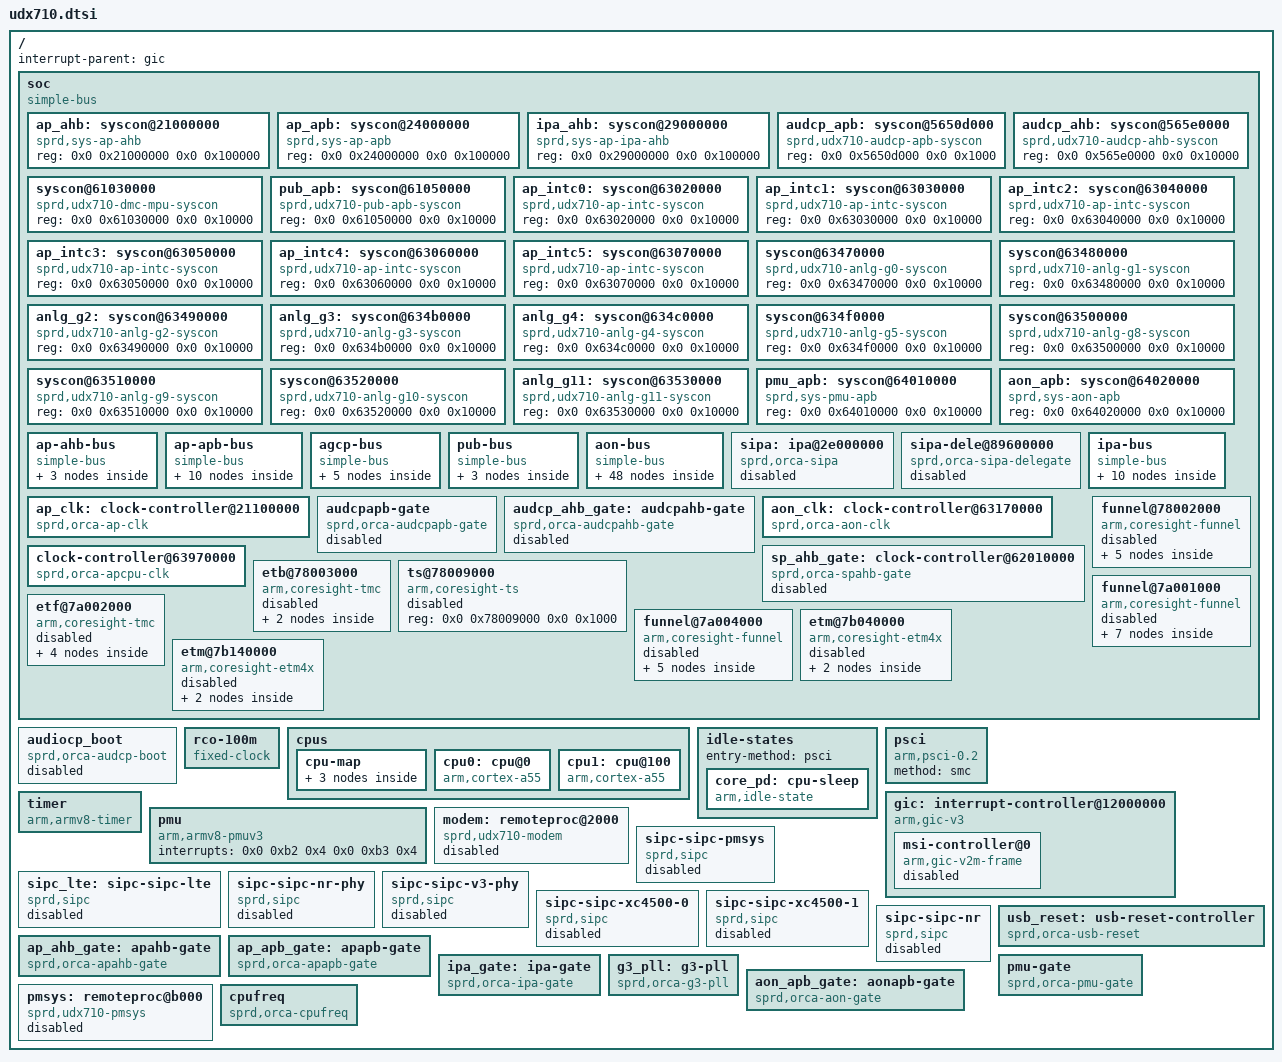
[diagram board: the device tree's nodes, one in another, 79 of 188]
// SPDX-License-Identifier: GPL-2.0-only
/* UDX710 controllers and silicon resources. The board supplies ext_26m and
 * ext_32k clock inputs and selects CPU frequency policy. */

/ {
	interrupt-parent = <&gic>;
	#address-cells = <0x2>;
	#size-cells = <0x2>;
	soc {
		compatible = "simple-bus";
		#address-cells = <0x2>;
		#size-cells = <0x2>;
		ranges;
		ap_ahb: syscon@21000000 {
			compatible = "sprd,sys-ap-ahb", "syscon";
			#syscon-cells = <0x2>;
			reg = <0x0 0x21000000 0x0 0x100000>;
		};
		ap_apb: syscon@24000000 {
			compatible = "sprd,sys-ap-apb", "syscon";
			#syscon-cells = <0x2>;
			reg = <0x0 0x24000000 0x0 0x100000>;
		};
		ipa_ahb: syscon@29000000 {
			compatible = "sprd,sys-ap-ipa-ahb", "syscon";
			#syscon-cells = <0x2>;
			reg = <0x0 0x29000000 0x0 0x100000>;
		};
		audcp_apb: syscon@5650d000 {
			compatible = "sprd,udx710-audcp-apb-syscon", "syscon";
			#syscon-cells = <0x2>;
			reg = <0x0 0x5650d000 0x0 0x1000>;
		};
		audcp_ahb: syscon@565e0000 {
			compatible = "sprd,udx710-audcp-ahb-syscon", "syscon";
			#syscon-cells = <0x2>;
			reg = <0x0 0x565e0000 0x0 0x10000>;
		};
		syscon@61030000 {
			compatible = "sprd,udx710-dmc-mpu-syscon", "syscon";
			#syscon-cells = <0x2>;
			reg = <0x0 0x61030000 0x0 0x10000>;
		};
		pub_apb: syscon@61050000 {
			compatible = "sprd,udx710-pub-apb-syscon", "syscon";
			#syscon-cells = <0x2>;
			reg = <0x0 0x61050000 0x0 0x10000>;
		};
		ap_intc0: syscon@63020000 {
			compatible = "sprd,udx710-ap-intc-syscon", "syscon";
			#syscon-cells = <0x2>;
			reg = <0x0 0x63020000 0x0 0x10000>;
		};
		ap_intc1: syscon@63030000 {
			compatible = "sprd,udx710-ap-intc-syscon", "syscon";
			#syscon-cells = <0x2>;
			reg = <0x0 0x63030000 0x0 0x10000>;
		};
		ap_intc2: syscon@63040000 {
			compatible = "sprd,udx710-ap-intc-syscon", "syscon";
			#syscon-cells = <0x2>;
			reg = <0x0 0x63040000 0x0 0x10000>;
		};
		ap_intc3: syscon@63050000 {
			compatible = "sprd,udx710-ap-intc-syscon", "syscon";
			#syscon-cells = <0x2>;
			reg = <0x0 0x63050000 0x0 0x10000>;
		};
		ap_intc4: syscon@63060000 {
			compatible = "sprd,udx710-ap-intc-syscon", "syscon";
			#syscon-cells = <0x2>;
			reg = <0x0 0x63060000 0x0 0x10000>;
		};
		ap_intc5: syscon@63070000 {
			compatible = "sprd,udx710-ap-intc-syscon", "syscon";
			#syscon-cells = <0x2>;
			reg = <0x0 0x63070000 0x0 0x10000>;
		};
		syscon@63470000 {
			compatible = "sprd,udx710-anlg-g0-syscon", "syscon";
			#syscon-cells = <0x2>;
			reg = <0x0 0x63470000 0x0 0x10000>;
		};
		syscon@63480000 {
			compatible = "sprd,udx710-anlg-g1-syscon", "syscon";
			#syscon-cells = <0x2>;
			reg = <0x0 0x63480000 0x0 0x10000>;
		};
		anlg_g2: syscon@63490000 {
			compatible = "sprd,udx710-anlg-g2-syscon", "syscon";
			#syscon-cells = <0x2>;
			reg = <0x0 0x63490000 0x0 0x10000>;
		};
		anlg_g3: syscon@634b0000 {
			compatible = "sprd,udx710-anlg-g3-syscon", "syscon";
			#syscon-cells = <0x2>;
			reg = <0x0 0x634b0000 0x0 0x10000>;
		};
		anlg_g4: syscon@634c0000 {
			compatible = "sprd,udx710-anlg-g4-syscon", "syscon";
			#syscon-cells = <0x2>;
			reg = <0x0 0x634c0000 0x0 0x10000>;
		};
		syscon@634f0000 {
			compatible = "sprd,udx710-anlg-g5-syscon", "syscon";
			#syscon-cells = <0x2>;
			reg = <0x0 0x634f0000 0x0 0x10000>;
		};
		syscon@63500000 {
			compatible = "sprd,udx710-anlg-g8-syscon", "syscon";
			#syscon-cells = <0x2>;
			reg = <0x0 0x63500000 0x0 0x10000>;
		};
		syscon@63510000 {
			compatible = "sprd,udx710-anlg-g9-syscon", "syscon";
			#syscon-cells = <0x2>;
			reg = <0x0 0x63510000 0x0 0x10000>;
		};
		syscon@63520000 {
			compatible = "sprd,udx710-anlg-g10-syscon", "syscon";
			#syscon-cells = <0x2>;
			reg = <0x0 0x63520000 0x0 0x10000>;
		};
		anlg_g11: syscon@63530000 {
			compatible = "sprd,udx710-anlg-g11-syscon", "syscon";
			#syscon-cells = <0x2>;
			reg = <0x0 0x63530000 0x0 0x10000>;
		};
		pmu_apb: syscon@64010000 {
			compatible = "sprd,sys-pmu-apb", "syscon";
			#syscon-cells = <0x2>;
			reg = <0x0 0x64010000 0x0 0x10000>;
		};
		aon_apb: syscon@64020000 {
			compatible = "sprd,sys-aon-apb", "syscon";
			#syscon-cells = <0x2>;
			reg = <0x0 0x64020000 0x0 0x10000>;
		};
		ap-ahb-bus {
			compatible = "simple-bus";
			#address-cells = <0x2>;
			#size-cells = <0x2>;
			ranges;
			ap_dma: dma-controller@21200000 {
				compatible = "sprd,orca-dma";
				reg = <0x0 0x21200000 0x0 0x4000>;
				interrupts = <0x0 0x32 0x4>;
				#dma-cells = <0x1>;
				clock-names = "enable";
				clocks = <&ap_ahb_gate 0x4>;
				dma-channels = <0x1c>;
			};
			nand-controller@21300000 {
			status = "disabled";
				compatible = "sprd,orca-nandc";
				reg = <0x0 0x21300000 0x0 0x1000>;
				interrupts = <0x0 0x3b 0x4>;
				clock-names = "nandc_clk", "nandc_ecc_clk", "nandc_parent_sdr", "nandc_parent_ddr", "nandc_ahb_enable", "nandc_ecc_enable", "nandc_26m_enable", "nandc_1x_enable", "nandc_2x_enable";
				clocks = <&aon_clk 0x2e &ap_clk 0x2 &g3_pll 0xf &g3_pll 0xe &ap_ahb_gate 0x1 &ap_ahb_gate 0x2 &ap_ahb_gate 0x3 &aon_apb_gate 0x69 &aon_apb_gate 0x6a>;
				#address-cells = <0x1>;
				#size-cells = <0x0>;
			};
			sdio@26100000 {
				status = "disabled";
				compatible = "sprd,sdhc-r11p1";
				reg = <0x0 0x26100000 0x0 0x1000>;
				interrupts = <0x0 0x3c 0x4>;
				clock-names = "sdio_clk", "sdio_clk_source", "sdio_ahb_enable";
				clocks = <&aon_clk 0x2c &g3_pll 0x0 &ap_ahb_gate 0xb>;
			};
		};
		ap-apb-bus {
			compatible = "simple-bus";
			#address-cells = <0x2>;
			#size-cells = <0x2>;
			ranges;
			serial@24100000 {
			status = "disabled";
				compatible = "sprd,sc9836-uart";
				reg = <0x0 0x24100000 0x0 0x100>;
				interrupts = <0x0 0x3 0x4>;
				clock-names = "enable", "uart", "source";
				clocks = <&ap_apb_gate 0x1 &ap_clk 0x6 &ext_26m>;
			};
			i2c@24200000 {
				compatible = "sprd,orca-i2c";
				reg = <0x0 0x24200000 0x0 0x1000>;
				interrupts = <0x0 0xb 0x4>;
				clock-frequency = <0x61a80>;
				#address-cells = <0x1>;
				#size-cells = <0x0>;
				status = "disabled";
				clock-names = "enable", "i2c", "source";
				clocks = <&ap_apb_gate 0x2 &ap_clk 0x7 &ext_26m>;
			};
			i2c@24300000 {
				compatible = "sprd,orca-i2c";
				reg = <0x0 0x24300000 0x0 0x1000>;
				interrupts = <0x0 0xc 0x4>;
				clock-frequency = <0x61a80>;
				#address-cells = <0x1>;
				#size-cells = <0x0>;
				status = "disabled";
				clock-names = "enable", "i2c", "source";
				clocks = <&ap_apb_gate 0x3 &ap_clk 0x8 &ext_26m>;
			};
			i2c@24400000 {
				compatible = "sprd,orca-i2c";
				reg = <0x0 0x24400000 0x0 0x1000>;
				interrupts = <0x0 0xd 0x4>;
				clock-frequency = <0x61a80>;
				#address-cells = <0x1>;
				#size-cells = <0x0>;
				status = "disabled";
				clock-names = "enable", "i2c", "source";
				clocks = <&ap_apb_gate 0x4 &ap_clk 0x9 &ext_26m>;
			};
			i2c@24500000 {
				compatible = "sprd,orca-i2c";
				reg = <0x0 0x24500000 0x0 0x1000>;
				interrupts = <0x0 0xe 0x4>;
				clock-frequency = <0x61a80>;
				#address-cells = <0x1>;
				#size-cells = <0x0>;
				status = "disabled";
				clock-names = "enable", "i2c", "source";
				clocks = <&ap_apb_gate 0x5 &ap_clk 0xa &ext_26m>;
			};
			i2c@24600000 {
				compatible = "sprd,orca-i2c";
				reg = <0x0 0x24600000 0x0 0x1000>;
				interrupts = <0x0 0xf 0x4>;
				clock-frequency = <0x61a80>;
				#address-cells = <0x1>;
				#size-cells = <0x0>;
				status = "disabled";
				clock-names = "enable", "i2c", "source";
				clocks = <&ap_apb_gate 0x6 &ap_clk 0xb &ext_26m>;
			};
			spi@24700000 {
				compatible = "sprd,sc9860-spi", "sprd,orca-spi";
				reg = <0x0 0x24700000 0x0 0x1000>;
				interrupts = <0x0 0x7 0x4>;
				#address-cells = <0x1>;
				#size-cells = <0x0>;
				status = "disabled";
				clock-names = "enable", "spi", "source";
				clocks = <&ap_apb_gate 0x7 &aon_clk 0x30 &g3_pll 0x5>;
			};
			spi@24800000 {
				compatible = "sprd,sc9860-spi", "sprd,orca-spi";
				reg = <0x0 0x24800000 0x0 0x1000>;
				interrupts = <0x0 0x8 0x4>;
				#address-cells = <0x1>;
				#size-cells = <0x0>;
				status = "disabled";
				clock-names = "enable", "spi", "source";
				clocks = <&ap_apb_gate 0x9 &aon_clk 0x31 &g3_pll 0x5>;
			};
			spi@24900000 {
				compatible = "sprd,sc9860-spi", "sprd,orca-spi";
				reg = <0x0 0x24900000 0x0 0x1000>;
				interrupts = <0x0 0x9 0x4>;
				#address-cells = <0x1>;
				#size-cells = <0x0>;
				status = "disabled";
				clock-names = "enable", "spi", "source";
				clocks = <&ap_apb_gate 0xb &aon_clk 0x32 &g3_pll 0x5>;
			};
			i2s0: i2s@25000000 {
				compatible = "sprd,i2s";
				status = "disabled";
			};
		};
		agcp-bus {
			compatible = "simple-bus";
			#address-cells = <0x2>;
			#size-cells = <0x2>;
			ranges;
			vbc: vbc@56480000 {
				compatible = "sprd,roc1-vbc";
				#sound-dai-cells = <0x1>;
				reg = <0x0 0x56480000 0x0 0x1000>;
				sprd,syscon-agcp-ahb = <&audcp_ahb>;
				sprd,vbc-phy-offset = <0x55000000>;
				status = "disabled";
			};
			mcdt@56490000 {
				compatible = "sprd,roc1-mcdt";
				reg = <0x0 0x56490000 0x0 0x170>;
				interrupts = <0x0 0x76 0x4>;
				sprd,ap-addr-offset = <0x55000000>;
				status = "disabled";
			};
			audcp_dma: dma-controller@56580000 {
				compatible = "sprd,roc1-dma";
				reg = <0x0 0x56580000 0x0 0x4000>;
				interrupts = <0x0 0x75 0x4>;
				#dma-cells = <0x1>;
				#dma-channels = <0x20>;
				clock-names = "enable", "ashb_eb";
				clocks = <&audcp_ahb_gate 0x6 &audcp_ahb_gate 0xd>;
				status = "disabled";
			};
			audio-codec@56750000 {
				compatible = "sprd,audio-codec-dig-agcp";
				reg = <0x0 0x56750000 0x0 0x1000>;
				sprd,syscon-agcp-ahb = <&audcp_ahb>;
				status = "disabled";
			};
			agdsp-access {
				compatible = "sprd,agdsp-access";
				sprd,syscon-agcp-ahb = <&aon_apb>;
				sprd,syscon-pmu-apb = <&pmu_apb>;
				syscons = <&pmu_apb 0xcc 0x20 &pmu_apb 0xd4 0xf000 &pmu_apb 0x58c 0xff &pmu_apb 0x58c 0xff00 &aon_apb 0x648 0x20>;
				syscon-names = "audcp_pmu_sleep_ctrl", "audcp_pmu_slp_status", "audcp_pmu_pwr_status4", "audcp_pmu_pwr_status3", "ap_access_ena";
				sprd,dst = <0x5>;
				sprd,channel = <0x82>;
				sprd,mailbox-core = <0x5>;
				sprd,ddr-addr-offset = <0x0>;
				hwlocks = <&hwspinlock 0xb>;
				sprd,auto_agcp_access = <0x0>;
				status = "disabled";
			};
		};
		pub-bus {
			compatible = "simple-bus";
			#address-cells = <0x2>;
			#size-cells = <0x2>;
			ranges;
			dmc-mpu@61030000 {
				compatible = "sprd,orca-dmc-mpu";
				reg = <0x0 0x61030000 0x0 0x10000>;
				interrupts = <0x0 0x6f 0x4>;
				syscon-names = "irq_clr", "irq_en";
				syscons = <&pub_apb 0x32f0 0x200 &pub_apb 0x32f0 0x100>;
				sprd,channel-num = <0x7>;
				sprd,mpu-num = <0x10>;
				sprd,channel-names = "AP_DMA", "NR_CP1", "NR_CP2", "V3_MODEM1", "V3_MODEM2", "PS_CP", "AG_CP", "IPA", "TFT", "USB_PAM", "PCIE", "CM4", "SHARED0", "SHARED1", "SHARED2", "SHARED3";
				sprd,ranges = <0x0 0x0 0x0 0x0 0x0 0x0 0x0 0x0 0x0 0x0 0x0 0x0 0x0 0x0 0x0 0x0 0x0 0x0 0x0 0x0 0x0 0x0 0x0 0x0 0x0 0x0 0x0 0x0 0x0 0x0 0x0 0x0 0x0 0x0 0x0 0x0 0x0 0x0 0x0 0x0 0x0 0x0 0x0 0x0 0x0 0x0 0x0 0x0 0x0 0x0 0x0 0x0 0x0 0x0 0x0 0x0 0x0 0x0 0x0 0x0 0x0 0x0 0x0 0x0>;
				sprd,chn-config = <0x0 0x1 0x1 0x0 0x1 0x1 0x0 0x1 0x1 0x0 0x1 0x1 0x0 0x1 0x1 0x0 0x1 0x1 0x0 0x1 0x1 0x0 0x1 0x1 0x0 0x1 0x1 0x0 0x1 0x1 0x0 0x1 0x1 0x0 0x1 0x1 0x0 0x1 0x1 0x0 0x1 0x1 0x0 0x1 0x1 0x0 0x1 0x1>;
				sprd,id-config = <0x0 0x1 0x0 0x0 0x0 0xffff 0x0 0x0 0xffff 0x0 0x0 0xffff 0x0 0x0 0xffff 0x0 0x0 0xffff 0x0 0x0 0xffff 0x0 0x6 0x0 0x0 0x7 0x0 0x0 0xa 0x0 0x0 0xb 0x0 0x0 0x12 0x0 0x0 0x0 0xffff 0x0 0x0 0xffff 0x0 0x0 0xffff 0x0 0x0 0xffff>;
				sprd,port-map = <0x0 0x1 0x2 0x3 0x4 0x5 0x6 0x0 0x0 0x0 0x0 0x0 0x0 0x0 0x0 0x0>;
				sprd,ddr-offset = <0x80000000>;
				status = "disabled";
				sprd,panic;
			};
			dmc-controller@61050000 {
				compatible = "sprd,orca-dmc";
				reg = <0x0 0x61050000 0x0 0x7000 0x0 0x6000 0x0 0x1000>;
				status = "disabled";
			};
			ptm@61060000 {
				compatible = "sprd,orca-ptm";
				reg = <0x0 0x61060000 0x0 0x10000 0x0 0x78002000 0x0 0x1000 0x0 0x78003000 0x0 0x1000 0x0 0x78006000 0x0 0x1000>;
				interrupts = <0x0 0x6d 0x4>;
				clock-names = "clk_cs", "cs_src";
				clocks = <&aon_clk 0x26 &g3_pll 0xb>;
				sprd,funnel-port = <0x5>;
				sprd,ddr-chn = <0x7>;
				sprd,chn-name = "APCPU/miniAP/CS/AON", "NRCPU", "NRACC", "V3CPU", "V3ACC", "PSCP", "AGCP";
				status = "disabled";
			};
		};
		aon-bus {
			compatible = "simple-bus";
			#address-cells = <0x2>;
			#size-cells = <0x2>;
			ranges;
			eic_debounce: gpio@631d0000 {
				compatible = "sprd,orca-eic-debounce", "sprd,sharkl5-eic-debounce";
				reg = <0x0 0x631d0000 0x0 0x80 0x0 0x631e0000 0x0 0x80 0x0 0x631f0000 0x0 0x80 0x0 0x63200000 0x0 0x80>;
				gpio-controller;
				#gpio-cells = <0x2>;
				interrupt-controller;
				#interrupt-cells = <0x2>;
				interrupts = <0x0 0x48 0x4>;
			};
			gpio@631d0080 {
				compatible = "sprd,orca-eic-latch", "sprd,sharkl5-eic-latch";
				reg = <0x0 0x631d0080 0x0 0x20 0x0 0x631e0080 0x0 0x20 0x0 0x631f0080 0x0 0x20 0x0 0x63200080 0x0 0x20>;
				gpio-controller;
				#gpio-cells = <0x2>;
				interrupt-controller;
				#interrupt-cells = <0x2>;
				interrupts = <0x0 0x48 0x4>;
			};
			eic_async: gpio@631d00a0 {
				compatible = "sprd,orca-eic-async", "sprd,sharkl5-eic-async";
				reg = <0x0 0x631d00a0 0x0 0x20 0x0 0x631e00a0 0x0 0x20 0x0 0x631f00a0 0x0 0x20 0x0 0x632000a0 0x0 0x20>;
				gpio-controller;
				#gpio-cells = <0x2>;
				interrupt-controller;
				#interrupt-cells = <0x2>;
				interrupts = <0x0 0x48 0x4>;
			};
			gpio@631d00c0 {
				compatible = "sprd,orca-eic-sync", "sprd,sharkl5-eic-sync";
				reg = <0x0 0x631d00c0 0x0 0x20 0x0 0x631e00c0 0x0 0x20 0x0 0x631f00c0 0x0 0x20 0x0 0x632000c0 0x0 0x20>;
				gpio-controller;
				#gpio-cells = <0x2>;
				interrupt-controller;
				#interrupt-cells = <0x2>;
				interrupts = <0x0 0x48 0x4>;
			};
			timer@63260000 {
				compatible = "sprd,orca-timer";
				reg = <0x0 0x63260000 0x0 0x20>;
				interrupts = <0x0 0x47 0x4>;
				clocks = <&ext_32k>;
				status = "disabled";
			};
			timer@63260020 {
				compatible = "sprd,orca-suspend-timer";
				reg = <0x0 0x63260020 0x0 0x20>;
				clocks = <&ext_32k>;
				status = "disabled";
			};
			serial@620e0000 {
				compatible = "sprd,sc9836-uart-ex";
				reg = <0x0 0x620e0000 0x0 0x100>;
				interrupts = <0x0 0x1 0x4>;
				status = "disabled";
				clock-names = "enable", "uart", "source";
				clocks = <&sp_ahb_gate 0x0 &aon_clk 0xc &ext_26m>;
			};
			i2c@632c0000 {
				compatible = "sprd,orca-hw-i2c";
				reg = <0x0 0x632c0000 0x0 0x1000>;
				interrupts = <0x0 0x44 0x4>;
				clock-frequency = <0x61a80>;
				#address-cells = <0x1>;
				#size-cells = <0x0>;
				status = "disabled";
			};
			gpio: gpio@632d0000 {
				compatible = "sprd,orca-gpio", "sprd,sc9860-gpio";
				reg = <0x0 0x632d0000 0x0 0x10000>;
				gpio-controller;
				#gpio-cells = <0x2>;
				interrupt-controller;
				#interrupt-cells = <0x2>;
				interrupts = <0x0 0x3d 0x4>;
			};
			mailbox: mailbox@63300000 {
				compatible = "sprd,orca-mailbox";
				reg = <0x0 0x63300000 0x0 0x1000 0x0 0x63310000 0x0 0x10000>;
				interrupts = <0x0 0x52 0x4 0x0 0x53 0x4>;
				status = "okay";
				#mbox-cells = <0x1>;
				interrupt-names = "inbox", "outbox";
				clocks = <&aon_apb_gate 0x20>;
				clock-names = "enable";
			};
			ap_efuse: efuse@63400000 {
				compatible = "sprd,orca-efuse";
				reg = <0x0 0x63400000 0x0 0x10000>;
				clock-names = "enable";
				hwlocks = <&hwspinlock 0x8>;
				clocks = <&aon_apb_gate 0x1e>;
				nvmem-layout {
					compatible = "fixed-layout";
					#address-cells = <0x1>;
					#size-cells = <0x1>;
					soc_uid: uid@b4 {
						reg = <0xb4 0x8>;
					};
					thm2_sen1_92: thm2-sen1@92 {
						reg = <0x92 0x4>;
						bits = <0x0 0x8>;
					};
					thm2_sen2_93: thm2-sen2@93 {
						reg = <0x93 0x4>;
						bits = <0x0 0x8>;
					};
					thm2_sign_94: thm2-sign@94 {
						reg = <0x94 0x4>;
						bits = <0x0 0x1>;
					};
					thm2_ratio_94: thm2-ratio@94 {
						reg = <0x94 0x4>;
						bits = <0x1 0x7>;
					};
					thm2_sen0_95: thm2-sen0@95 {
						reg = <0x95 0x4>;
						bits = <0x0 0x8>;
					};
					thm0_sign_98: thm0-sign@98 {
						reg = <0x98 0x4>;
						bits = <0x0 0x1>;
					};
					thm0_ratio_98: thm0-ratio@98 {
						reg = <0x98 0x4>;
						bits = <0x1 0x7>;
					};
					thm0_sen0_99: thm0-sen0@99 {
						reg = <0x99 0x4>;
						bits = <0x0 0x8>;
					};
					thm1_sign_9a: thm1-sign@9a {
						reg = <0x9a 0x4>;
						bits = <0x0 0x1>;
					};
					thm1_ratio_9a: thm1-ratio@9a {
						reg = <0x9a 0x4>;
						bits = <0x1 0x7>;
					};
					thm1_sen0_9b: thm1-sen0@9b {
						reg = <0x9b 0x4>;
						bits = <0x0 0x8>;
					};
				};
			};
			pinctrl: pinctrl@63450000 {
				compatible = "sprd,orca-pinctrl";
				reg = <0x0 0x63450000 0x0 0x10000>;
			};
			modem-dbg-log@63610000 {
				compatible = "sprd,dbg-log-orca";
				reg = <0x0 0x63610000 0x0 0x4000>;
				sprd,syscon-dsi-apb = <&anlg_g11>;
				sprd,ch-name = "TRAINING", "TPIU", "DBUS", "V3", "NR";
				sprd,ch-index = <0xf 0x1 0x0 0x2 0x3>;
				sprd,dcfix;
				status = "disabled";
				clock-names = "serdes_eb", "ana_eb", "dphy_cfg_eb", "dphy_ref_eb", "dsi_ref_eb";
				clocks = <&aon_apb_gate 0x17 &aon_apb_gate 0x29 &aon_apb_gate 0x11 &aon_apb_gate 0x12 &aon_apb_gate 0x74>;
			};
			modem-dbg-log@63620000 {
				compatible = "sprd,dbg-log-orca";
				reg = <0x0 0x63620000 0x0 0x4000>;
				sprd,syscon-dsi-apb = <&anlg_g11>;
				sprd,ch-name = "TRAINING", "TPIU", "NR";
				sprd,ch-index = <0xf 0x1 0x0>;
				sprd,dcfix;
				status = "disabled";
				clock-names = "serdes_eb", "ana_eb", "dphy_cfg_eb", "dphy_ref_eb", "dsi_ref_eb";
				clocks = <&aon_apb_gate 0x18 &aon_apb_gate 0x29 &aon_apb_gate 0x13 &aon_apb_gate 0x14 &aon_apb_gate 0x75>;
			};
			modem-dbg-log@63630000 {
				compatible = "sprd,dbg-log-orca";
				reg = <0x0 0x63630000 0x0 0x4000>;
				sprd,syscon-dsi-apb = <&anlg_g11>;
				sprd,ch-name = "TRAINING", "NR";
				sprd,ch-index = <0xf 0x0>;
				sprd,dcfix;
				status = "disabled";
				clock-names = "serdes_eb", "ana_eb", "dphy_cfg_eb", "dphy_ref_eb", "dsi_ref_eb";
				clocks = <&aon_apb_gate 0x19 &aon_apb_gate 0x29 &aon_apb_gate 0x15 &aon_apb_gate 0x16 &aon_apb_gate 0x76>;
			};
			djtag@63650000 {
				compatible = "sprd,djtag";
				reg = <0x0 0x63650000 0x0 0x1000>;
				syscon-names = "soft_rst";
				syscons = <&aon_apb 0x20c 0x400>;
				clock-names = "enable", "tck";
				clocks = <&aon_apb_gate 0x3 &aon_apb_gate 0x2>;
				hwlocks = <&hwspinlock 0xa>;
				hwlock-names = "djtag";
				#address-cells = <0x1>;
				#size-cells = <0x0>;
				status = "disabled";
				ap-busmonitor@0 {
					compatible = "sprd,orca-busmonitor";
					interrupts = <0x0 0x38 0x4>;
					reg = <0x0>;
					sprd,bm-num = <0xe>;
					sprd,bm-name = "AP_DMA", "SDIO_MST", "NANDC", "EMMC", "USB3.0", "AP_AON", "IPA", "TFT", "SDIO_SLV", "USB_PAM", "USB3.1", "PCIE_MSTR", "PAM_WIFI", "AP_IPA_DDR";
					sprd,bm-type = <0x1 0x1 0x1 0x1 0x1 0x1 0x1 0x1 0x1 0x1 0x1 0x1 0x1 0x1>;
					sprd,bm-dap = <0x1 0x2 0x3 0x4 0x5 0x6 0x7 0x8 0x9 0xa 0xb 0xc 0xd 0xe>;
					sprd,bm-config = <0x0 0x1 0x1 0x0 0x1 0x1 0x0 0x1 0x1 0x0 0x1 0x1 0x0 0x1 0x1 0x0 0x1 0x1 0x0 0x1 0x1 0x0 0x1 0x1 0x0 0x1 0x1 0x0 0x1 0x1 0x0 0x1 0x1 0x0 0x1 0x1 0x0 0x1 0x1 0x0 0x1 0x1>;
					sprd,bm-id = <0x0 0x0 0x0 0x0 0x0 0x0 0x0 0x0 0x0 0x0 0x0 0x0 0x0 0x0 0x0 0x0 0x0 0x0 0x0 0x0 0x0 0x0 0x0 0x0 0x0 0x0 0x0 0x0 0x0 0x0 0x0 0x0 0x0 0x0 0x0 0x0 0x0 0x0 0x0 0x0 0x0 0x0>;
					sprd,bm-ranges = <0x0 0x0 0x0 0x0 0x0 0x0 0x0 0x0 0x0 0x0 0x0 0x0 0x0 0x0 0x0 0x0 0x0 0x0 0x0 0x0 0x0 0x0 0x0 0x0 0x0 0x0 0x0 0x0>;
					status = "disabled";
				};
				apcpu-busmonitor@1 {
					compatible = "sprd,orca-busmonitor";
					interrupts = <0x0 0xa5 0x4>;
					reg = <0x1>;
					sprd,bm-num = <0x2>;
					sprd,bm-name = "DSU", "ETR";
					sprd,bm-type = <0x1 0x1>;
					sprd,bm-dap = <0x1 0x2>;
					sprd,bm-config = <0x0 0x1 0x1 0x0 0x1 0x1>;
					sprd,bm-id = <0x0 0x0 0x0 0x0 0x0 0x0>;
					sprd,bm-ranges = <0x0 0x0 0x0 0x0>;
					status = "disabled";
				};
				pscp-busmonitor@2 {
					compatible = "sprd,orca-busmonitor";
					interrupts = <0x0 0x51 0x4>;
					reg = <0x2>;
					sprd,bm-num = <0xe>;
					sprd,bm-name = "R8_CACHE", "R8_LLPP", "R8_FPP0", "R8_FPP1", "V3_SEC", "DMA_LINK0", "DMA_LINK_4C", "DMA", "SDIO", "NR_SEC0", "NR_SEC1", "FROM_MINIAP", "FROM_NRCP", "TO_DDR";
					sprd,bm-type = <0x1 0x1 0x1 0x1 0x1 0x1 0x1 0x1 0x1 0x1 0x1 0x1 0x1 0x1>;
					sprd,bm-dap = <0x0 0x1 0x2 0x3 0x4 0x5 0x6 0x7 0x8 0x9 0xa 0xb 0xc 0xd>;
					sprd,bm-config = <0x0 0x1 0x1 0x0 0x1 0x1 0x0 0x1 0x1 0x0 0x1 0x1 0x0 0x1 0x1 0x0 0x1 0x1 0x0 0x1 0x1 0x0 0x1 0x1 0x0 0x1 0x1 0x0 0x1 0x1 0x0 0x1 0x1 0x0 0x1 0x1 0x0 0x1 0x1 0x0 0x1 0x1>;
					sprd,bm-id = <0x0 0x0 0x0 0x0 0x0 0x0 0x0 0x0 0x0 0x0 0x0 0x0 0x0 0x0 0x0 0x0 0x0 0x0 0x0 0x0 0x0 0x0 0x0 0x0 0x0 0x0 0x0 0x0 0x0 0x0 0x0 0x0 0x0 0x0 0x0 0x0 0x0 0x0 0x0 0x0 0x0 0x0>;
					sprd,bm-ranges = <0x0 0x0 0x0 0x0 0x0 0x0 0x0 0x0 0x0 0x0 0x0 0x0 0x0 0x0 0x0 0x0 0x0 0x0 0x0 0x0 0x0 0x0 0x0 0x0 0x0 0x0 0x0 0x0>;
					status = "disabled";
				};
				v3phy-busmonitor@3 {
					compatible = "sprd,orca-busmonitor";
					interrupts = <0x0 0x51 0x4>;
					reg = <0x3>;
					sprd,bm-num = <0x10>;
					sprd,bm-name = "PHY_R5_l2_CACHE", "PHY_DMA", "PHY_DMA_LINK", "FROM_PS", "FROM_LW", "PHY_R5_LLPP", "PS_R5_L2_CACHE", "PS_SEC", "PS_TFT", "PS_DMA_LINK0", "PS_DMA_LINK4C", "PS_DMA", "PS_SDIO", "PS_R5_LLPP", "LW_HARQBUF", "LW_TO_DDR";
					sprd,bm-type = <0x1 0x1 0x1 0x1 0x1 0x1 0x1 0x1 0x1 0x1 0x1 0x1 0x1 0x1 0x1 0x1>;
					sprd,bm-dap = <0x1 0x2 0x3 0x4 0x5 0x6 0x7 0x8 0x9 0xa 0xb 0xc 0xd 0xe 0xf 0x10>;
					sprd,bm-config = <0x0 0x1 0x1 0x0 0x1 0x1 0x0 0x1 0x1 0x0 0x1 0x1 0x0 0x1 0x1 0x0 0x1 0x1 0x0 0x1 0x1 0x0 0x1 0x1 0x0 0x1 0x1 0x0 0x1 0x1 0x0 0x1 0x1 0x0 0x1 0x1 0x0 0x1 0x1 0x0 0x1 0x1 0x0 0x1 0x1 0x0 0x1 0x1>;
					sprd,bm-id = <0x0 0x0 0x0 0x0 0x0 0x0 0x0 0x0 0x0 0x0 0x0 0x0 0x0 0x0 0x0 0x0 0x0 0x0 0x0 0x0 0x0 0x0 0x0 0x0 0x0 0x0 0x0 0x0 0x0 0x0 0x0 0x0 0x0 0x0 0x0 0x0 0x0 0x0 0x0 0x0 0x0 0x0 0x0 0x0 0x0 0x0 0x0 0x0>;
					sprd,bm-ranges = <0x0 0x0 0x0 0x0 0x0 0x0 0x0 0x0 0x0 0x0 0x0 0x0 0x0 0x0 0x0 0x0 0x0 0x0 0x0 0x0 0x0 0x0 0x0 0x0 0x0 0x0 0x0 0x0 0x0 0x0 0x0 0x0>;
					status = "disabled";
				};
				nrcp-busmonitor@4 {
					compatible = "sprd,orca-busmonitor";
					interrupts = <0x0 0x51 0x4>;
					reg = <0x4>;
					sprd,bm-num = <0xe>;
					sprd,bm-name = "R8_CACHE", "R8_LLPP", "R8_FPP0", "R8_FPP1", "DMA", "NR_SEC", "NR_UL", "NR_DL", "NR_SYNC", "XC0_EPP", "XC0_EDP", "XC1_EPP", "XC1_EDP", "ACC_DMA";
					sprd,bm-type = <0x1 0x1 0x1 0x1 0x1 0x1 0x1 0x1 0x1 0x1 0x1 0x1 0x1 0x1>;
					sprd,bm-dap = <0x1 0x2 0x3 0x4 0x5 0x6 0x7 0x8 0x9 0xa 0xb 0xc 0xd 0xe>;
					sprd,bm-config = <0x0 0x1 0x1 0x0 0x1 0x1 0x0 0x1 0x1 0x0 0x1 0x1 0x0 0x1 0x1 0x0 0x1 0x1 0x0 0x1 0x1 0x0 0x1 0x1 0x0 0x1 0x1 0x0 0x1 0x1 0x0 0x1 0x1 0x0 0x1 0x1 0x0 0x1 0x1 0x0 0x1 0x1>;
					sprd,bm-id = <0x0 0x0 0x0 0x0 0x0 0x0 0x0 0x0 0x0 0x0 0x0 0x0 0x0 0x0 0x0 0x0 0x0 0x0 0x0 0x0 0x0 0x0 0x0 0x0 0x0 0x0 0x0 0x0 0x0 0x0 0x0 0x0 0x0 0x0 0x0 0x0 0x0 0x0 0x0 0x0 0x0 0x0>;
					sprd,bm-ranges = <0x0 0x0 0x0 0x0 0x0 0x0 0x0 0x0 0x0 0x0 0x0 0x0 0x0 0x0 0x0 0x0 0x0 0x0 0x0 0x0 0x0 0x0 0x0 0x0 0x0 0x0 0x0 0x0>;
					status = "disabled";
				};
				audcp-busmonitor@5 {
					compatible = "sprd,orca-busmonitor";
					interrupts = <0x0 0x51 0x4>;
					reg = <0x5>;
					sprd,bm-num = <0x4>;
					sprd,bm-name = "auddsp_d", "dma_ap", "from_aon", "dma_cp";
					sprd,bm-type = <0x1 0x1 0x1 0x1>;
					sprd,bm-dap = <0x0 0x1 0x2 0x3>;
					sprd,bm-config = <0x0 0x1 0x1 0x0 0x1 0x1 0x0 0x1 0x1 0x0 0x1 0x1>;
					sprd,bm-id = <0x0 0x0 0x0 0x0 0x0 0x0 0x0 0x0 0x0 0x0 0x0 0x0>;
					sprd,bm-ranges = <0x0 0x0 0x0 0x0 0x0 0x0 0x0 0x0>;
					status = "disabled";
				};
				aon-busmonitor@7 {
					compatible = "sprd,orca-busmonitor";
					interrupts = <0x0 0x51 0x4>;
					reg = <0x7>;
					sprd,bm-num = <0x7>;
					sprd,bm-name = "minAP", "V3_MODEM", "AGCP", "PSCP", "NRCP", "CM4", "DAP";
					sprd,bm-type = <0x1 0x1 0x1 0x1 0x1 0x1 0x1>;
					sprd,bm-dap = <0x0 0x1 0x2 0x3 0x4 0x5 0x6>;
					sprd,bm-config = <0x0 0x1 0x1 0x0 0x1 0x1 0x0 0x1 0x1 0x0 0x1 0x1 0x0 0x1 0x1 0x0 0x1 0x1 0x0 0x1 0x1>;
					sprd,bm-id = <0x0 0x0 0x0 0x0 0x0 0x0 0x0 0x0 0x0 0x0 0x0 0x0 0x0 0x0 0x0 0x0 0x0 0x0 0x0 0x0 0x0>;
					sprd,bm-ranges = <0x64020000 0x64020010 0x64020000 0x64020010 0x64020000 0x64020010 0x64020000 0x64020010 0x64020000 0x64020010 0x64020000 0x64020010 0x64020000 0x64020010>;
					status = "disabled";
				};
			};
			apcpu_wdt: watchdog@63940000 {
				compatible = "sprd,orca-wdt";
				reg = <0x0 0x63940000 0x0 0x10000>;
				interrupts = <0x0 0x4f 0x4>;
				timeout-sec = <0xc>;
				clock-names = "enable", "rtc_enable";
				clocks = <&aon_apb_gate 0x46 &aon_apb_gate 0x50>;
			};
			hwspinlock: hwspinlock@64000000 {
				compatible = "sprd,orca-hwspinlock", "sprd,hwspinlock-r3p0";
				reg = <0x0 0x64000000 0x0 0x10000>;
				#hwlock-cells = <0x1>;
				clock-names = "enable";
				clocks = <&aon_apb_gate 0x27>;
			};
			apb-busmonitor@64030000 {
				compatible = "sprd,orca-apb-busmonitor";
				reg = <0x0 0x64030000 0x0 0x1000>;
				interrupts = <0x0 0x27 0x4>;
				sprd,target-addr = <0x0 0x0>;
				sprd,target-data = <0x0 0x0>;
				status = "disabled";
			};
		};
		sipa: ipa@2e000000 {
		status = "disabled";
			compatible = "sprd,orca-sipa";
			sprd,modem = <&modem>;
			reg = <0x0 0x2e000000 0x0 0x2000 0x0 0x28000000 0x0 0x40000>;
			reg-names = "glb-base", "iram-base";
			interrupts = <0x0 0x2e 0x4>;
			interrupt-names = "local_ipa_irq";
			sprd,enable-syscon = <&ipa_ahb 0x0 0x80>;
		};
		sipa-dele@89600000 {
		reg-names = "reg-base";
		status = "disabled";
		/* Register resource; firmware adds its shared DDR region. */
		reg = <0 0x21180000 0 0x10000>;
			compatible = "sprd,orca-sipa-delegate";
			sprd,cp-transport = <&sipc_lte>;
			sprd,sipa = <&sipa>;
		};
		ipa-bus {
			compatible = "simple-bus";
			#address-cells = <0x2>;
			#size-cells = <0x2>;
			ranges;
			usb3@21400000 {
				compatible = "sprd,orca-dwc3";
				reg = <0x0 0x21400000 0x0 0x100000>;
				clocks = <&ap_ahb_gate 0x6 &ap_ahb_gate 0x7 &ap_ahb_gate 0x8>;
				clock-names = "core_clk", "ref_clk", "susp_clk";
				phys = <&usb0_phy>;
				phy-names = "usb";
				#address-cells = <0x2>;
				#size-cells = <0x2>;
				ranges;
				status = "disabled";
				usb@21400000 {
					compatible = "snps,dwc3";
					reg = <0x0 0x21400000 0x0 0x100000>;
					interrupts = <0x0 0x10 0x4>;
					interrupt-names = "dwc_usb3";
					phys = <&usb0_phy &usb0_phy>;
					phy-names = "usb2-phy", "usb3-phy";
					phy_type = "utmi_wide";
					snps,usb3-u1u2-disable;
					snps,dis_u3_susphy_quirk;
					snps,dis_u2_susphy_quirk;
					snps,overlap_check_quirk;
					snps,ep_out_aligned_size_quirk;
					snps,disconnect_event_quirk;
					snps,dis-del-phy-power-chg-quirk;
				};
			};
			usb3@29100000 {
			status = "disabled";
				compatible = "sprd,orca-dwc3";
				reg = <0x0 0x29100000 0x0 0x100000>;
				clocks = <&ipa_gate 0x0 &ipa_gate 0x1 &ipa_gate 0x2>;
				clock-names = "core_clk", "ref_clk", "susp_clk";
				#address-cells = <0x2>;
				#size-cells = <0x2>;
				ranges;
				phys = <&usb1_phy>;
				phy-names = "usb";
				usb1_dwc3: usb@29100000 {
					compatible = "snps,dwc3";
					reg = <0x0 0x29100000 0x0 0x100000>;
					interrupts = <0x0 0x13 0x4>;
					interrupt-names = "dwc_usb3";
					phy_type = "utmi_wide";
					snps,dis_u3_susphy_quirk;
					snps,dis_u2_susphy_quirk;
					snps,req_p1p2p3_quirk;
					snps,del_phy_power_chg_quirk;
					phys = <&usb1_phy &usb1_phy>;
					phy-names = "usb2-phy", "usb3-phy";
				};
			};
			pcie0@2b100000 {
			status = "disabled";
				compatible = "sprd,orca-pcie";
				reg = <0x0 0x2b100000 0x0 0x100000 0x2 0x7000000 0x0 0x100000>;
				reg-names = "dbi", "config";
				#address-cells = <0x3>;
				#size-cells = <0x2>;
				device_type = "pci";
				ranges = <0x1000000 0x0 0x0 0x2 0x6000000 0x0 0x1000000 0x3000000 0x0 0x10000000 0x2 0x0 0x0 0x6000000>;
				bus-range = <0x0 0xf>;
				num-lanes = <0x1>;
				num-vectors = <0x100>;
				num-viewport = <0x8>;
				clocks = <&ipa_gate 5>, <&ipa_gate 6>;
				clock-names = "core", "aux";
				sprd,pcie-startup-syscons = <&aon_apb 0x0 0x0 0x800 0x3ff 0x1 &aon_apb 0x0 0x0 0x800 0x10000 0x10000 &anlg_g2 0x1 0x0 0x28 0xf000 0x5000 &anlg_g2 0x0 0x0 0xc 0x1 0x1 &anlg_g2 0x1 0x0 0x8 0xffff0000 0x10000 &aon_apb 0x0 0x0 0x564 0x200 0x200 &pmu_apb 0x0 0x0 0x394 0x200 0x0 &pmu_apb 0x0 0x0 0x394 0x100 0x100 &pmu_apb 0x0 0x0 0x394 0x2000 0x0 &ipa_ahb 0x0 0x0 0x0 0x200 0x0 &ipa_ahb 0x0 0x0 0x0 0x40 0x40 &ipa_ahb 0x0 0x0 0x0 0x20 0x20 &pmu_apb 0x0 0x0 0x3a0 0x40 0x40 &pmu_apb 0x0 0x96 0x3a0 0x10 0x10 &pmu_apb 0x0 0x0 0x3a0 0x10 0x0>;
				sprd,pcie-shutdown-syscons = <&pmu_apb 0x0 0x0 0x3a0 0x10 0x10 &ipa_ahb 0x0 0x0 0x0 0x20 0x0 &pmu_apb 0x0 0x0 0x394 0x200 0x200>;
				sprd,pcie-resume-syscons = <&pmu_apb 0x0 0xc8 0x394 0x200 0x0 &pmu_apb 0x2 0x0 0x418 0xf000 0x4000 &ipa_ahb 0x0 0xc8 0x0 0x20 0x20 &pmu_apb 0x0 0x64 0x3a0 0x10 0x10 &pmu_apb 0x0 0x7d0 0x3a0 0x10 0x0>;
				sprd,pcie-suspend-syscons = <&pmu_apb 0x0 0x5 0x3a0 0x10 0x10 &ipa_ahb 0x0 0x0 0x0 0x20 0x0 &pmu_apb 0x0 0x0 0x394 0x200 0x200>;
				dummy@0 {
					label = "msi_int";
					interrupt-parent = <&gic>;
					#interrupt-cells = <0x3>;
					interrupts = <0x0 0x16 0x4>;
				};
			};
			pcie1@2b100000 {
				compatible = "sprd,pcie-ep", "snps,dw-pcie";
				reg = <0x0 0x2b100000 0x0 0x100000 0x0 0x2b108000 0x0 0x2000 0x2 0x0 0x2 0x0>;
				reg-names = "dbi", "dbi2", "addr_space";
				interrupts = <0x0 0x37 0x4>;
				num-lanes = <0x1>;
				num-ib-windows = <0x6>;
				num-ob-windows = <0x8>;
				pcie-perst-gpios = <&eic_debounce 0x1e 0x0>;
				status = "disabled";
			};
			pamu3: pamu3@2b300000 {
			status = "disabled";
				compatible = "sprd,orca-pamu3";
				clocks = <&ipa_gate 0x8>;
				clock-names = "pamu3_clk";
				reg = <0x0 0x2b300000 0x0 0x10000>;
				reg-names = "pamu3_glb_regs";
				sprd,dwc3 = <&usb1_dwc3>;
				sprd,sipa = <&sipa>;
				resets = <&usb_reset 0x1>;
				reset-names = "pamu3";
			};
			usb0_phy: ssphy0@634d0000 {
				compatible = "sprd,orca1-ssphy0";
				reg = <0x0 0x634d0000 0x0 0x10000>;
				reg-names = "ssphy_glb_regs";
				sprd,syscon-aon-apb = <&aon_apb>;
				sprd,syscon-ap-ahb = <&ap_ahb>;
				sprd,syscon-ipa-ahb = <&ipa_ahb>;
				sprd,syscon-anag4 = <&anlg_g4>;
				status = "disabled";
				#phy-cells = <0>;
				resets = <&usb_reset 0>;
			};
			usb1_phy: ssphy@634e0000 {
			status = "disabled";
				compatible = "sprd,orca1-ssphy1";
				reg = <0x0 0x634e0000 0x0 0x10000>;
				reg-names = "ssphy_glb_regs";
				sprd,syscon-aon-apb = <&aon_apb>;
				sprd,syscon-ap-ahb = <&ap_ahb>;
				sprd,syscon-ipa-ahb = <&ipa_ahb>;
				sprd,syscon-anag4 = <&anlg_g4>;
				#phy-cells = <0x0>;
				resets = <&usb_reset 0x1>;
			};
		};
		ap_clk: clock-controller@21100000 {
			compatible = "sprd,orca-ap-clk";
			reg = <0x0 0x21100000 0x0 0x1000>;
			clocks = <&ext_26m>;
			#clock-cells = <0x1>;
		};
		audcpapb-gate {
			compatible = "sprd,orca-audcpapb-gate";
			sprd,syscon = <&audcp_apb>;
			clocks = <&ext_26m>;
			#clock-cells = <0x1>;
			status = "disabled";
		};
		audcp_ahb_gate: audcpahb-gate {
			compatible = "sprd,orca-audcpahb-gate";
			sprd,syscon = <&audcp_ahb>;
			clocks = <&ext_26m>;
			#clock-cells = <0x1>;
			status = "disabled";
		};
		aon_clk: clock-controller@63170000 {
			compatible = "sprd,orca-aon-clk";
			reg = <0x0 0x63170000 0x0 0x1000>;
			clocks = <&ext_26m>;
			#clock-cells = <0x1>;
		};
		clock-controller@63970000 {
			compatible = "sprd,orca-apcpu-clk";
			reg = <0x0 0x63970000 0x0 0x1000>;
			clocks = <&ext_26m>;
			#clock-cells = <0x1>;
		};
		sp_ahb_gate: clock-controller@62010000 {
			compatible = "sprd,orca-spahb-gate";
			reg = <0x0 0x62010000 0x0 0x3000>;
			clocks = <&ext_26m>;
			#clock-cells = <0x1>;
			status = "disabled";
		};
		funnel@78002000 {
			compatible = "arm,coresight-funnel", "arm,primecell";
			reg = <0x0 0x78002000 0x0 0x1000>;
			clocks = <&ext_26m>;
			clock-names = "apb_pclk";
			status = "disabled";
			ports {
				#address-cells = <0x1>;
				#size-cells = <0x0>;
				port@0 {
					reg = <0x0>;
					funnel_78002000_port_0_endpoint: endpoint {
						remote-endpoint = <&etb_78003000_port_endpoint>;
					};
				};
				port@1 {
					reg = <0x0>;
					funnel_78002000_port_1_endpoint: endpoint {
						slave-mode;
						remote-endpoint = <&funnel_7a004000_port_0_endpoint>;
					};
				};
			};
		};
		etb@78003000 {
			compatible = "arm,coresight-tmc", "arm,primecell";
			reg = <0x0 0x78003000 0x0 0x1000>;
			clocks = <&ext_26m>;
			clock-names = "apb_pclk";
			status = "disabled";
			port {
				etb_78003000_port_endpoint: endpoint {
					slave-mode;
					remote-endpoint = <&funnel_78002000_port_0_endpoint>;
				};
			};
		};
		ts@78009000 {
			compatible = "arm,coresight-ts", "arm,primecell";
			reg = <0x0 0x78009000 0x0 0x1000>;
			status = "disabled";
		};
		funnel@7a001000 {
			compatible = "arm,coresight-funnel", "arm,primecell";
			reg = <0x0 0x7a001000 0x0 0x1000>;
			clocks = <&ext_26m>;
			clock-names = "apb_pclk";
			status = "disabled";
			ports {
				#address-cells = <0x1>;
				#size-cells = <0x0>;
				port@0 {
					reg = <0x0>;
					funnel_7a001000_port_0_endpoint: endpoint {
						remote-endpoint = <&etf_7a002000_port_1_endpoint>;
					};
				};
				port@1 {
					reg = <0x0>;
					funnel_7a001000_port_1_endpoint: endpoint {
						slave-mode;
						remote-endpoint = <&etm_7b040000_port_endpoint>;
					};
				};
				port@2 {
					reg = <0x1>;
					funnel_7a001000_port_2_endpoint: endpoint {
						slave-mode;
						remote-endpoint = <&etm_7b140000_port_endpoint>;
					};
				};
			};
		};
		etf@7a002000 {
			compatible = "arm,coresight-tmc", "arm,primecell";
			reg = <0x0 0x7a002000 0x0 0x1000>;
			clocks = <&ext_26m>;
			clock-names = "apb_pclk";
			status = "disabled";
			port@0 {
				etf_7a002000_port_0_endpoint: endpoint {
					remote-endpoint = <&funnel_7a004000_port_1_endpoint>;
				};
			};
			port@1 {
				etf_7a002000_port_1_endpoint: endpoint {
					slave-mode;
					remote-endpoint = <&funnel_7a001000_port_0_endpoint>;
				};
			};
		};
		funnel@7a004000 {
			compatible = "arm,coresight-funnel", "arm,primecell";
			reg = <0x0 0x7a004000 0x0 0x1000>;
			clocks = <&ext_26m>;
			clock-names = "apb_pclk";
			status = "disabled";
			ports {
				#address-cells = <0x1>;
				#size-cells = <0x0>;
				port@0 {
					reg = <0x0>;
					funnel_7a004000_port_0_endpoint: endpoint {
						remote-endpoint = <&funnel_78002000_port_1_endpoint>;
					};
				};
				port@1 {
					reg = <0x0>;
					funnel_7a004000_port_1_endpoint: endpoint {
						slave-mode;
						remote-endpoint = <&etf_7a002000_port_0_endpoint>;
					};
				};
			};
		};
		etm@7b040000 {
			compatible = "arm,coresight-etm4x", "arm,primecell";
			reg = <0x0 0x7b040000 0x0 0x1000>;
			cpu = <&cpu0>;
			clocks = <&ext_26m &aon_clk 0x26 &g3_pll 0x4>;
			clock-names = "apb_pclk", "clk_cs", "cs_src";
			status = "disabled";
			port {
				etm_7b040000_port_endpoint: endpoint {
					remote-endpoint = <&funnel_7a001000_port_1_endpoint>;
				};
			};
		};
		etm@7b140000 {
			compatible = "arm,coresight-etm4x", "arm,primecell";
			reg = <0x0 0x7b140000 0x0 0x1000>;
			cpu = <&cpu1>;
			clocks = <&ext_26m &aon_clk 0x26 &g3_pll 0x4>;
			clock-names = "apb_pclk", "clk_cs", "cs_src";
			status = "disabled";
			port {
				etm_7b140000_port_endpoint: endpoint {
					remote-endpoint = <&funnel_7a001000_port_2_endpoint>;
				};
			};
		};
	};
	audiocp_boot {
		compatible = "sprd,orca-audcp-boot";
		syscons = <&pmu_apb 0x60 0x2000000 &pmu_apb 0x5c 0x1000000 &pmu_apb 0xcc 0x10 &pmu_apb 0xb0 0x400 &pmu_apb 0xb0 0x200 &pmu_apb 0x6b0 0x3ff &pmu_apb 0x58c 0xff &pmu_apb 0x58c 0xff00 &pmu_apb 0xd4 0xf000 &aon_apb 0x60c 0xffff &aon_apb 0x640 0xffffffff &aon_apb 0x644 0x1>;
		syscon-names = "sysshutdown", "coreshutdown", "deepsleep", "corereset", "sysreset", "reset_sel", "sysstatus", "corestatus", "sleepstatus", "bootprotect", "bootvector", "bootaddress_sel";
		status = "disabled";
	};
	rco-100m {
		compatible = "fixed-clock";
		#clock-cells = <0x0>;
		clock-frequency = <0x5f5e100>;
		clock-output-names = "rco-100m";
	};
	cpus {
		#address-cells = <0x2>;
		#size-cells = <0x0>;
		cpu-map {
			cluster0 {
				core0 {
					cpu = <&cpu0>;
				};
				core1 {
					cpu = <&cpu1>;
				};
			};
		};
		cpu0: cpu@0 {
			device_type = "cpu";
			compatible = "arm,cortex-a55";
			reg = <0x0 0x0>;
			enable-method = "psci";
			cpu-idle-states = <&core_pd>;
			#cooling-cells = <0x2>;
		};
		cpu1: cpu@100 {
			device_type = "cpu";
			compatible = "arm,cortex-a55";
			reg = <0x0 0x100>;
			enable-method = "psci";
			cpu-idle-states = <&core_pd>;
			#cooling-cells = <0x2>;
		};
	};
	idle-states {
		entry-method = "psci";
		core_pd: cpu-sleep {
			compatible = "arm,idle-state";
			entry-latency-us = <0xfa0>;
			exit-latency-us = <0xfa0>;
			min-residency-us = <0x2710>;
			local-timer-stop;
			arm,psci-suspend-param = <0x10000>;
		};
	};
	psci {
		compatible = "arm,psci-0.2";
		method = "smc";
	};
	gic: interrupt-controller@12000000 {
		compatible = "arm,gic-v3";
		#interrupt-cells = <0x3>;
		#address-cells = <0x2>;
		#size-cells = <0x2>;
		ranges;
		redistributor-stride = <0x0 0x20000>;
		#redistributor-regions = <0x1>;
		interrupt-controller;
		reg = <0x0 0x12000000 0x0 0x20000 0x0 0x12040000 0x0 0x100000>;
		interrupts = <0x1 0x9 0x4>;
		msi-controller@0 {
			compatible = "arm,gic-v2m-frame";
			msi-controller;
			reg = <0x0 0x0 0x0 0x1000>;
			status = "disabled";
		};
	};
	timer {
		compatible = "arm,armv8-timer";
		interrupts = <0x1 0xd 0x4 0x1 0xe 0x4 0x1 0xb 0x4 0x1 0xa 0x4>;
		arm,no-tick-in-suspend;
	};
	pmu {
		compatible = "arm,armv8-pmuv3";
		interrupts = <0x0 0xb2 0x4 0x0 0xb3 0x4>;
	};
	modem: remoteproc@2000 {
		/* CP, V3 PHY and NR boot IRAM: device specification p.547. */
		reg = <0 0x2000 0 0x1000>, <0 0x4000 0 0x1000>,
		      <0 0x5000 0 0x1000>;
		reg-names = "cp-iram", "v3-iram", "nr-iram";
		status = "disabled";
		compatible = "sprd,udx710-modem";
		sprd,aon-apb = <&aon_apb>;
		sprd,pmu-apb = <&pmu_apb>;
	};
	sipc-sipc-pmsys {
		status = "disabled";
		compatible = "sprd,sipc";
		sprd,name = "sipc-pmsys";
		sprd,type = "mbox";
		sprd,dst = <0x6>;
		sprd,core = <0x1>;
		sprd,smem-info = <0x8400 0x60008400 0x2000>;
		mboxes = <&mailbox 0x1>;
		mbox-names = "smsg";
		sprd,smem-type = <0x0>;
	};
	sipc_lte: sipc-sipc-lte {
		status = "disabled";
		compatible = "sprd,sipc";
		sprd,name = "sipc-lte";
		sprd,type = "mbox";
		sprd,dst = <0x5>;
		sprd,core = <0x2>;
		mboxes = <&mailbox 0x2>;
		mbox-names = "smsg";
		sprd,smem-type = <0x0>;
	};
	sipc-sipc-nr-phy {
		status = "disabled";
		compatible = "sprd,sipc";
		sprd,name = "sipc-nr-phy";
		sprd,type = "mbox";
		sprd,dst = <0x7>;
		sprd,core = <0x6>;
		mboxes = <&mailbox 0x6>;
		mbox-names = "smsg";
		sprd,smem-type = <0x0>;
	};
	sipc-sipc-v3-phy {
		status = "disabled";
		compatible = "sprd,sipc";
		sprd,name = "sipc-v3-phy";
		sprd,type = "mbox";
		sprd,dst = <0x8>;
		sprd,core = <0x4>;
		mboxes = <&mailbox 0x4>;
		mbox-names = "smsg";
		sprd,smem-type = <0x0>;
	};
	sipc-sipc-xc4500-0 {
		status = "disabled";
		compatible = "sprd,sipc";
		sprd,name = "sipc-xc4500-0";
		sprd,type = "mbox";
		sprd,dst = <0x1>;
		sprd,core = <0x7>;
		mboxes = <&mailbox 0x7>;
		mbox-names = "smsg";
		sprd,smem-type = <0x0>;
	};
	sipc-sipc-xc4500-1 {
		status = "disabled";
		compatible = "sprd,sipc";
		sprd,name = "sipc-xc4500-1";
		sprd,type = "mbox";
		sprd,dst = <0x2>;
		sprd,core = <0x8>;
		mboxes = <&mailbox 0x8>;
		mbox-names = "smsg";
		sprd,smem-type = <0x0>;
	};
	sipc-sipc-nr {
		compatible = "sprd,sipc";
		sprd,name = "sipc-nr";
		sprd,type = "pcie";
		sprd,dst = <0x0>;
		sprd,client = <0x1>;
		sprd,ep-fun = <0x0>;
		sprd,smem-type = <0x1>;
		sprd,high-offset = <0x0 0x0>;
		interrupts = <0x0 0x4 0x4>;
		status = "disabled";
	};
	usb_reset: usb-reset-controller {
		compatible = "sprd,orca-usb-reset";
		#reset-cells = <0x1>;
		sprd,ap-ahb = <&ap_ahb>;
		sprd,ipa-ahb = <&ipa_ahb>;
	};
	ap_ahb_gate: apahb-gate {
		compatible = "sprd,orca-apahb-gate";
		sprd,syscon = <&ap_ahb>;
		clocks = <&ext_26m>;
		#clock-cells = <0x1>;
	};

	ap_apb_gate: apapb-gate {
		compatible = "sprd,orca-apapb-gate";
		sprd,syscon = <&ap_apb>;
		clocks = <&ext_26m>;
		#clock-cells = <0x1>;
	};

	ipa_gate: ipa-gate {
		compatible = "sprd,orca-ipa-gate";
		sprd,syscon = <&ipa_ahb>;
		clocks = <&ext_26m>;
		#clock-cells = <0x1>;
	};

	g3_pll: g3-pll {
		compatible = "sprd,orca-g3-pll";
		sprd,syscon = <&anlg_g3>;
		clocks = <&ext_26m>;
		#clock-cells = <0x1>;
	};

	pmu-gate {
		compatible = "sprd,orca-pmu-gate";
		sprd,syscon = <&pmu_apb>;
		clocks = <&ext_26m>;
		#clock-cells = <0x1>;
	};

	aon_apb_gate: aonapb-gate {
		compatible = "sprd,orca-aon-gate";
		sprd,syscon = <&aon_apb>;
		clocks = <&ext_26m>;
		#clock-cells = <0x1>;
	};

};

/* UDX710 ADI controller hardware; PMIC selection is board-specific. */
&{/soc/aon-bus} {
	udx710_adi: spi@63a00000 {
		compatible = "sprd,orca-adi";
		reg = <0x0 0x63a00000 0x0 0x200000>;
		#address-cells = <0x1>;
		#size-cells = <0x0>;
		status = "disabled";
	};
};

/* UDX710 on-die thermal blocks and silicon calibration connections. */
&{/soc/aon-bus} {
	thm0: thermal@63410000 {
		compatible = "sprd,orca-thermal";
		reg = <0x0 0x63410000 0x0 0x10000>;
		clock-names = "enable", "functional";
		clocks = <&aon_apb_gate 0x34 &aon_clk 0x10>;
		#thermal-sensor-cells = <0x1>;
		nvmem-cells = <&thm0_sign_98 &thm0_ratio_98>;
		nvmem-cell-names = "thm_sign_cal", "thm_ratio_cal";
		#address-cells = <0x1>;
		#size-cells = <0x0>;
		status = "disabled";
		apcpu0-sensor@0 {
			reg = <0x0>;
			nvmem-cells = <&thm0_sen0_99>;
			nvmem-cell-names = "sen_delta_cal";
		};
	};

	thm1: thermal@63420000 {
		compatible = "sprd,orca-thermal";
		reg = <0x0 0x63420000 0x0 0x10000>;
		clock-names = "enable", "functional";
		clocks = <&aon_apb_gate 0x35 &aon_clk 0x11>;
		#thermal-sensor-cells = <0x1>;
		nvmem-cells = <&thm1_sign_9a &thm1_ratio_9a>;
		nvmem-cell-names = "thm_sign_cal", "thm_ratio_cal";
		#address-cells = <0x1>;
		#size-cells = <0x0>;
		status = "disabled";
		nrcp-sensor@0 {
			reg = <0x0>;
			nvmem-cells = <&thm1_sen0_9b>;
			nvmem-cell-names = "sen_delta_cal";
		};
	};

	thm2: thermal@63430000 {
		compatible = "sprd,orca-thermal";
		reg = <0x0 0x63430000 0x0 0x10000>;
		clock-names = "enable", "functional";
		clocks = <&aon_apb_gate 0x47 &aon_clk 0x12>;
		#thermal-sensor-cells = <0x1>;
		nvmem-cells = <&thm2_sign_94 &thm2_ratio_94>;
		nvmem-cell-names = "thm_sign_cal", "thm_ratio_cal";
		#address-cells = <0x1>;
		#size-cells = <0x0>;
		status = "disabled";
		apcpu1-sensor@0 {
			reg = <0x0>;
			nvmem-cells = <&thm2_sen0_95>;
			nvmem-cell-names = "sen_delta_cal";
		};
		ank0-sensor@1 {
			reg = <0x1>;
			nvmem-cells = <&thm2_sen1_92>;
			nvmem-cell-names = "sen_delta_cal";
		};
		ank1-sensor@2 {
			reg = <0x2>;
			nvmem-cells = <&thm2_sen2_93>;
			nvmem-cell-names = "sen_delta_cal";
		};
	};
};

/* UDX710 CM4 SRAM window and its AON reset controller. */
/ {
	pmsys: remoteproc@b000 {
		compatible = "sprd,udx710-pmsys";
		reg = <0 0xb000 0 0xdc00>;
		sprd,aon-apb = <&aon_apb>;
		status = "disabled";
	};
};

/ {
	cpufreq {
		compatible = "sprd,orca-cpufreq";
		status = "okay";
	};
};
